# RL6845_IP_SVD register map
Vendor: Realtek
Registers are 32-bit, read-write, reset 0x0 unless marked. A register's access mark holds for its fields unless they carry their own. Offsets are from the block's base; [hi:lo] are bit positions; {n}, {i} and the like mark numbered series.

## PAGE1 (part 2 of 2)
Base 0x40000000
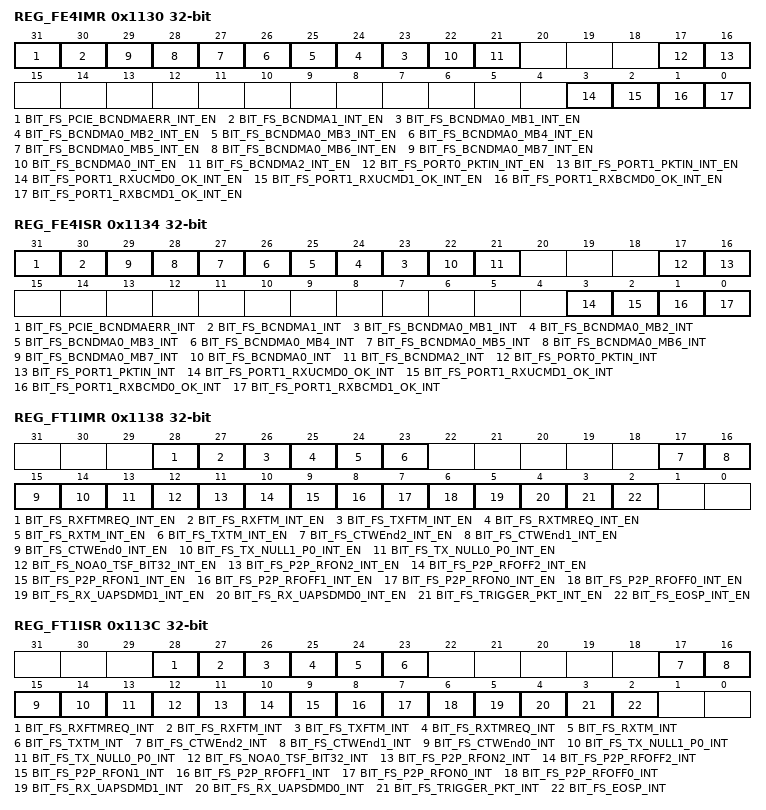
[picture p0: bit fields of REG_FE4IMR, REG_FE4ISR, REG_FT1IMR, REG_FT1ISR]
0x1130 REG_FE4IMR
  [31] BIT_FS_PCIE_BCNDMAERR_INT_EN — PCIE BCN DMA error interrupt
  [30] BIT_FS_BCNDMA1_INT_EN — When BCNDMA interval arrives before TBTT1, this interrupt informs MCU to prepare related beacon tasks.
  [n+22] BIT_FS_BCNDMA0_MB{n}_INT_EN (n=1..7) — When BCNDMA interval arrives before TBTT0_MB{n}, this interrupt informs MCU to prepare related beacon tasks.
  [22] BIT_FS_BCNDMA0_INT_EN — When BCNDMA interval arrives before TBTT0_MB0, this interrupt informs MCU to prepare related beacon tasks.
  [21] BIT_FS_BCNDMA2_INT_EN — When BCNDMA interval arrives before TBTT2, this interrupt informs MCU to prepare related beacon tasks.
  [17] BIT_FS_PORT0_PKTIN_INT_EN — port 0 packet assign to queue interrupt
  [16] BIT_FS_PORT1_PKTIN_INT_EN — port 1 packet assign to queue interrupt
  [3] BIT_FS_PORT1_RXUCMD0_OK_INT_EN — port 1 rx unicast packet with more data = 0 ok interrupt
  [2] BIT_FS_PORT1_RXUCMD1_OK_INT_EN — port 1 rx unicast packet with more data = 1 ok interrupt
  [1] BIT_FS_PORT1_RXBCMD0_OK_INT_EN — port 1 rx broadcast packet with more data = 0 ok interrupt
  [0] BIT_FS_PORT1_RXBCMD1_OK_INT_EN — port 1 rx broadcast packet with more data = 1 ok interrupt
0x1134 REG_FE4ISR ro
  [31] BIT_FS_PCIE_BCNDMAERR_INT — PCIE BCN DMA error interrupt
  [30] BIT_FS_BCNDMA1_INT — When BCNDMA interval arrives before TBTT1, this interrupt informs MCU to prepare related beacon tasks.
  [n+22] BIT_FS_BCNDMA0_MB{n}_INT (n=1..7) — When BCNDMA interval arrives before TBTT0_MB{n}, this interrupt informs MCU to prepare related beacon tasks.
  [22] BIT_FS_BCNDMA0_INT — When BCNDMA interval arrives before TBTT0_MB0, this interrupt informs MCU to prepare related beacon tasks.
  [21] BIT_FS_BCNDMA2_INT — When BCNDMA interval arrives before TBTT2, this interrupt informs MCU to prepare related beacon tasks.
  [17] BIT_FS_PORT0_PKTIN_INT — port 0 packet assign to queue interrupt
  [16] BIT_FS_PORT1_PKTIN_INT — port 1 packet assign to queue interrupt
  [3] BIT_FS_PORT1_RXUCMD0_OK_INT — port 1 rx unicast packet with more data = 0 ok interrupt
  [2] BIT_FS_PORT1_RXUCMD1_OK_INT — port 1 rx unicast packet with more data = 1 ok interrupt
  [1] BIT_FS_PORT1_RXBCMD0_OK_INT — port 1 rx broadcast packet with more data = 0 ok interrupt
  [0] BIT_FS_PORT1_RXBCMD1_OK_INT — port 1 rx broadcast packet with more data = 1 ok interrupt
0x1138 REG_FT1IMR
  [28] BIT_FS_RXFTMREQ_INT_EN — If BIT_RXFTMREQ_INT_EN =1. When HW receive FTMREQ packet, it will generate interrupt to firmware.
  [27] BIT_FS_RXFTM_INT_EN — If BIT_RXFTM_INT_EN =1. When HW receive FTM and transmit ACK frame successfully, the BB generate FTM report. It will generate interrupt to firmware.
  [26] BIT_FS_TXFTM_INT_EN — If BIT_TXFTM_INT_EN =1. When HW transmit FTM and receive ACK frame successfully, the BB generate FTM report. It will generate interrupt to firmware.
  [25] BIT_FS_RXTMREQ_INT_EN — If BIT_RXTMREQ_INT_EN =1. When HW receive TMREQ packet, it will generate interrupt to firmware.
  [24] BIT_FS_RXTM_INT_EN — If BIT_RXTM_INT_EN =1. When HW receive TM and transmit ACK frame successfully. It will generate interrupt to firmware.
  [23] BIT_FS_TXTM_INT_EN — If BIT_TXTM_INT_EN =1. When HW transmit TM and receive ACK frame successfully. It will generate interrupt to firmware.
  [17] BIT_FS_CTWEnd2_INT_EN — CTWindow End NOA2 interrupt.
  [16] BIT_FS_CTWEnd1_INT_EN — CTWindow End NOA1 interrupt.
  [15] BIT_FS_CTWEnd0_INT_EN — CTWindow End NOA0 interrupt.
  [14] BIT_FS_TX_NULL1_P0_INT_EN — TX null 1 packet done interrupt
  [13] BIT_FS_TX_NULL0_P0_INT_EN — TX null 0 packet done interrupt
  [12] BIT_FS_NOA0_TSF_BIT32_INT_EN — NOA unit0 TSFT bit 32 toggle interrupt
  [11] BIT_FS_P2P_RFON2_INT_EN — P2P NoA RF on time indication 2 interrupt
  [10] BIT_FS_P2P_RFOFF2_INT_EN — P2P NoA RF off time indication 2 interrupt
  [9] BIT_FS_P2P_RFON1_INT_EN — P2P NoA RF on time indication 1 interrupt
  [8] BIT_FS_P2P_RFOFF1_INT_EN — P2P NoA RF off time indication 1 interrupt
  [7] BIT_FS_P2P_RFON0_INT_EN — P2P NoA RF on time indication 0 interrupt
  [6] BIT_FS_P2P_RFOFF0_INT_EN — P2P NoA RF off time indication 0 interrupt
  [5] BIT_FS_RX_UAPSDMD1_INT_EN — Setting this bit indicates Rx pkt is matched with one of below: 1.) QoS Unicast data frame with MD=1, UAPSD=0 2.) NonQoS Unicast data frame with MD=1
  [4] BIT_FS_RX_UAPSDMD0_INT_EN — Setting this bit indicates Rx pkt is matched with one of below: 1.) QoS Unicast data frame with MD=0, UAPSD=0 2.) NonQoS Unicast data frame with MD=0
  [3] BIT_FS_TRIGGER_PKT_INT_EN — tx TRIGGER_PKT interrupt
  [2] BIT_FS_EOSP_INT_EN — EOSP_INT interrupt mask
0x113C REG_FT1ISR ro
  [28] BIT_FS_RXFTMREQ_INT — If BIT_RXFTMREQ_INT_EN =1. When HW receive FTMREQ packet, it will generate interrupt to firmware.
  [27] BIT_FS_RXFTM_INT — If BIT_RXFTM_INT_EN =1. When HW receive FTM and transmit ACK frame successfully, the BB generate FTM report. It will generate interrupt to firmware.
  [26] BIT_FS_TXFTM_INT — If BIT_TXFTM_INT_EN =1. When HW transmit FTM and receive ACK frame successfully, the BB generate FTM report. It will generate interrupt to firmware.
  [25] BIT_FS_RXTMREQ_INT — If BIT_RXTMREQ_INT_EN =1. When HW receive TMREQ packet, it will generate interrupt to firmware.
  [24] BIT_FS_RXTM_INT — If BIT_RXTM_INT_EN =1. When HW receive TM and transmit ACK frame successfully. It will generate interrupt to firmware.
  [23] BIT_FS_TXTM_INT — If BIT_TXTM_INT_EN =1. When HW transmit TM and receive ACK frame successfully. It will generate interrupt to firmware.
  [17] BIT_FS_CTWEnd2_INT — CTWindow End NOA2 interrupt.
  [16] BIT_FS_CTWEnd1_INT — CTWindow End NOA1 interrupt.
  [15] BIT_FS_CTWEnd0_INT — CTWindow End NOA0 interrupt.
  [14] BIT_FS_TX_NULL1_P0_INT — TX null 1 packet done interrupt
  [13] BIT_FS_TX_NULL0_P0_INT — TX null 0 packet done interrupt
  [12] BIT_FS_NOA0_TSF_BIT32_INT — NOA unit0 TSFT bit 32 toggle interrupt
  [11] BIT_FS_P2P_RFON2_INT — P2P NoA RF on time indication 2 interrupt
  [10] BIT_FS_P2P_RFOFF2_INT — P2P NoA RF off time indication 2 interrupt
  [9] BIT_FS_P2P_RFON1_INT — P2P NoA RF on time indication 1 interrupt
  [8] BIT_FS_P2P_RFOFF1_INT — P2P NoA RF off time indication 1 interrupt
  [7] BIT_FS_P2P_RFON0_INT — P2P NoA RF on time indication 0 interrupt
  [6] BIT_FS_P2P_RFOFF0_INT — P2P NoA RF off time indication 0 interrupt
  [5] BIT_FS_RX_UAPSDMD1_INT — Setting this bit indicates Rx pkt is matched with one of below: 1.) QoS Unicast data frame with MD=1, UAPSD=0 2.) NonQoS Unicast data frame with MD=1
  [4] BIT_FS_RX_UAPSDMD0_INT — Setting this bit indicates Rx pkt is matched with one of below: 1.) QoS Unicast data frame with MD=0, UAPSD=0 2.) NonQoS Unicast data frame with MD=0
  [3] BIT_FS_TRIGGER_PKT_INT — tx TRIGGER_PKT interrupt
  [2] BIT_FS_EOSP_INT — EOSP_INT interrupt mask
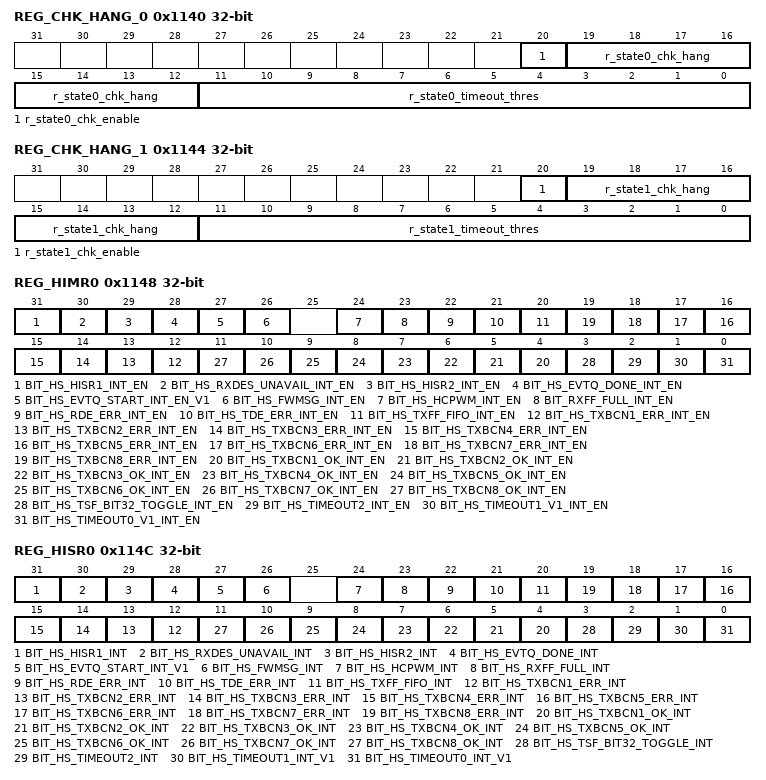
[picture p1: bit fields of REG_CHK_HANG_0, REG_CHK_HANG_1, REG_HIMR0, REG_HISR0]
0x1140 REG_CHK_HANG_0
  [20] r_state0_chk_enable — function enable of check hang of state_0
  [19:12] r_state0_chk_hang — when r_state0_chk_enable is set, if state_0 is the value is equal to r_state0_chk_hang, starts state0_timeout_timer
  [11:0] r_state0_timeout_thres — timeout threshold of state0_timeout_timer, unit:us
0x1144 REG_CHK_HANG_1
  [20] r_state1_chk_enable — function enable of check hang of state_1
  [19:12] r_state1_chk_hang — when r_state1_chk_enable is set, if state_1 is the value is equal to r_state1_chk_hang, starts state1_timeout_timer
  [11:0] r_state1_timeout_thres — timeout threshold of state0_timeout_timer, unit:us
0x1148 REG_HIMR0
  [31] BIT_HS_HISR1_INT_EN — HISR1 Indicator (HIISR1 andHIMR1 are true, this bit is set to 1)
  [30] BIT_HS_RXDES_UNAVAIL_INT_EN — Rx Descriptor Unavailable
  [29] BIT_HS_HISR2_INT_EN — HISR2 Indicator (HIISR2 andHIMR2 are true, this bit is set to 1)
  [28] BIT_HS_EVTQ_DONE_INT_EN — event queue done interrupt for NAN
  [27] BIT_HS_EVTQ_START_INT_EN_V1 — event queue start interrupt for NAN
  [26] BIT_HS_FWMSG_INT_EN — FW message interrupt,CPU to Host Command INT Status, Write 1 clear
  [24] BIT_HS_HCPWM_INT_EN — CPWM interrupt,CPU power Mode exchange INT Status, Write 1 clear
  [23] BIT_RXFF_FULL_INT_EN — Rxpktbuffer full interrupt
  [22] BIT_HS_RDE_ERR_INT_EN — Rxdma error interrupt
  [21] BIT_HS_TDE_ERR_INT_EN — Txdma error interrupt
  [20] BIT_HS_TXFF_FIFO_INT_EN — txpktbuffer full interrupt
  [n+11] BIT_HS_TXBCN{n}_ERR_INT_EN (n=1..8) — port0 BSSID{n-1} TX beacon error interrupt
  [n+3] BIT_HS_TXBCN{n}_OK_INT_EN (n=1..8) — port0 BSSID{n-1} TX beacon ok interrupt
  [3] BIT_HS_TSF_BIT32_TOGGLE_INT_EN — TSF Timer BIT32 toggle indication interrupt
  [2] BIT_HS_TIMEOUT2_INT_EN — tsf Timer2 interrupt
  [1] BIT_HS_TIMEOUT1_V1_INT_EN — tsf Timer1 interrupt
  [0] BIT_HS_TIMEOUT0_V1_INT_EN — tsf Timer0 interrupt
0x114C REG_HISR0 ro
  [31] BIT_HS_HISR1_INT — HISR1 Indicator (HIISR1 andHIMR1 are true, this bit is set to 1)
  [30] BIT_HS_RXDES_UNAVAIL_INT — Rx Descriptor Unavailable
  [29] BIT_HS_HISR2_INT — HISR2 Indicator (HIISR2 andHIMR2 are true, this bit is set to 1)
  [28] BIT_HS_EVTQ_DONE_INT — event queue done interrupt for NAN
  [27] BIT_HS_EVTQ_START_INT_V1 — event queue start interrupt for NAN
  [26] BIT_HS_FWMSG_INT — FW message interrupt,CPU to Host Command INT Status, Write 1 clear
  [24] BIT_HS_HCPWM_INT — CPWM interrupt,CPU power Mode exchange INT Status, Write 1 clear
  [23] BIT_HS_RXFF_FULL_INT — Rxpktbuffer full interrupt
  [22] BIT_HS_RDE_ERR_INT — Rxdma error interrupt
  [21] BIT_HS_TDE_ERR_INT — Txdma error interrupt
  [20] BIT_HS_TXFF_FIFO_INT — txpktbuffer full interrupt
  [n+11] BIT_HS_TXBCN{n}_ERR_INT (n=1..8) — port0 BSSID{n-1} TX beacon error interrupt
  [n+3] BIT_HS_TXBCN{n}_OK_INT (n=1..8) — port0 BSSID{n-1} TX beacon ok interrupt
  [3] BIT_HS_TSF_BIT32_TOGGLE_INT — TSF Timer BIT32 toggle indication interrupt
  [2] BIT_HS_TIMEOUT2_INT — tsf Timer2 interrupt
  [1] BIT_HS_TIMEOUT1_INT_V1 — tsf Timer1 interrupt
  [0] BIT_HS_TIMEOUT0_INT_V1 — tsf Timer0 interrupt
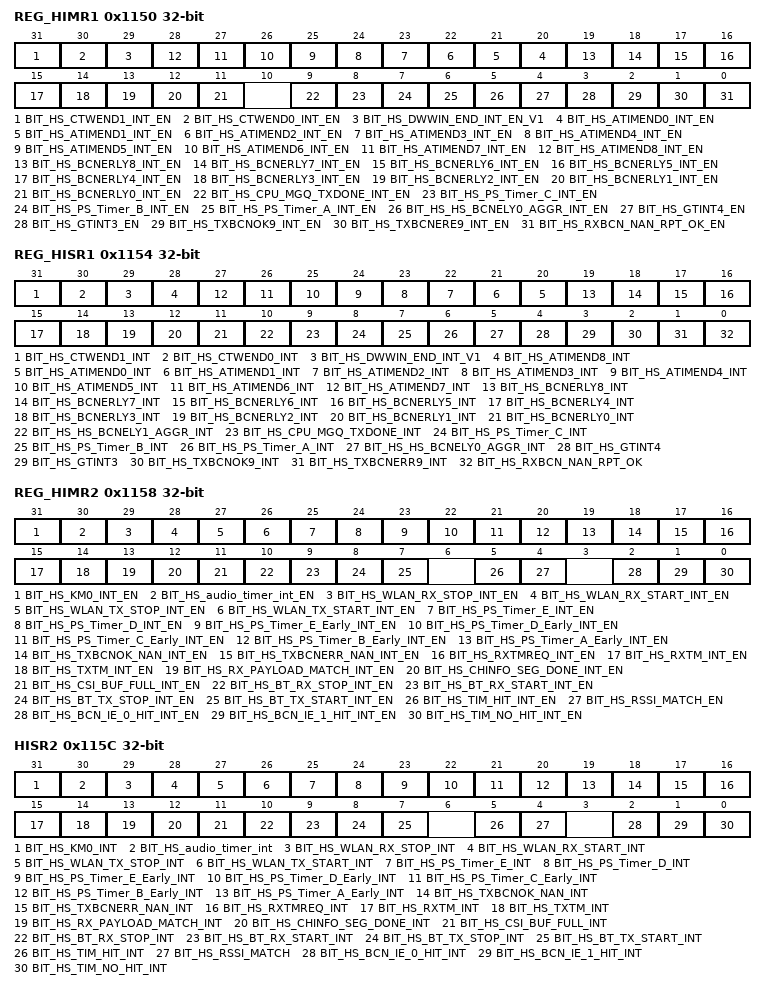
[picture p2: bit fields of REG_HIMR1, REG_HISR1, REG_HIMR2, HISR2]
0x1150 REG_HIMR1
  [31] BIT_HS_CTWEND1_INT_EN — Client1 traffic window end interrupt for P2P
  [30] BIT_HS_CTWEND0_INT_EN — Client0 traffic window end interrupt for P2P
  [29] BIT_HS_DWWIN_END_INT_EN_V1 — discovery window end interrupt for NAN
  [n+20] BIT_HS_ATIMEND{n}_INT_EN (n=0..8) — port0 BSSID{n} atimend interrupt
  [19] BIT_HS_BCNERLY8_INT_EN — port1 beacon early interrupt
  [18] BIT_HS_BCNERLY7_INT_EN — port0 BSSID7 beacon early interrupt , only valid under MBSSID mode
  [17] BIT_HS_BCNERLY6_INT_EN — port0 BSSID6 beacon early interrupt , only valid under MBSSID mode
  [16] BIT_HS_BCNERLY5_INT_EN — port0 BSSID5 beacon early interrupt , only valid under MBSSID mode
  [15] BIT_HS_BCNERLY4_INT_EN — port0 BSSID4 beacon early interrupt, only valid under MBSSID mode
  [14] BIT_HS_BCNERLY3_INT_EN — port0 BSSID3 beacon early interrupt , only valid under MBSSID mode
  [13] BIT_HS_BCNERLY2_INT_EN — port0 BSSID2 beacon early interrupt, only valid under MBSSID mode
  [12] BIT_HS_BCNERLY1_INT_EN — port0 BSSID1 beacon early interrupt , only valid under MBSSID mode
  [11] BIT_HS_BCNERLY0_INT_EN — This interrupt is issued at the time set by DRVERLYINT register before TBTT time for port 0 root bssid
  [9] BIT_HS_CPU_MGQ_TXDONE_INT_EN — CPU_MQG_TXDONE ineterrupt source when HW TX CPUMGQ packet success, it issue interrupt to host
  [8] BIT_HS_PS_Timer_C_INT_EN — PS_Timer_C interrupt source When the lower 4 bytes of TSF(that select by reg 0x1510[18:16]) matches the content of this register, the PS_Timer_C_INT interrupt is issued
  [7] BIT_HS_PS_Timer_B_INT_EN — PS_Timer_B interrupt source When the lower 4 bytes of TSF(that select by reg 0x1510[10:8]) matches the content of this register, the PS_Timer_B_INT interrupt is issued
  [6] BIT_HS_PS_Timer_A_INT_EN — PS_Timer_A interrupt source When the lower 4 bytes of TSF(that select by reg 0x1510[2:0]) matches the content of this register, the PS_Timer_A_INT interrupt is issued
  [5] BIT_HS_HS_BCNELY0_AGGR_INT_EN — port 0 Beacon early aggregation interrupt
  [4] BIT_HS_GTINT4_EN — When GTIMER4 expires, this bit is set to 1
  [3] BIT_HS_GTINT3_EN — When GTIMER3 expires, this bit is set to 1
  [2] BIT_HS_TXBCNOK9_INT_EN — PORT1 TX beacon OK interrupt
  [1] BIT_HS_TXBCNERE9_INT_EN — PORT1 TX beacon Error interrupt
  [0] BIT_HS_RXBCN_NAN_RPT_OK_EN — port2 rxbcn rpt and write to txrptbuf ok
0x1154 REG_HISR1 ro
  [31] BIT_HS_CTWEND1_INT — Client1 traffic window end interrupt for P2P
  [30] BIT_HS_CTWEND0_INT — Client0 traffic window end interrupt for P2P
  [29] BIT_HS_DWWIN_END_INT_V1 — discovery window end interrupt for NAN
  [28] BIT_HS_ATIMEND8_INT — port1 atimend interrupt
  [n+20] BIT_HS_ATIMEND{n}_INT (n=0..7) — port0 BSSID{n} atimend interrupt
  [19] BIT_HS_BCNERLY8_INT — port1 beacon early interrupt
  [18] BIT_HS_BCNERLY7_INT — port0 BSSID7 beacon early interrupt , only valid under MBSSID mode
  [17] BIT_HS_BCNERLY6_INT — port0 BSSID6 beacon early interrupt , only valid under MBSSID mode
  [16] BIT_HS_BCNERLY5_INT — port0 BSSID5 beacon early interrupt , only valid under MBSSID mode
  [15] BIT_HS_BCNERLY4_INT — port0 BSSID4 beacon early interrupt, only valid under MBSSID mode
  [14] BIT_HS_BCNERLY3_INT — port0 BSSID3 beacon early interrupt , only valid under MBSSID mode
  [13] BIT_HS_BCNERLY2_INT — port0 BSSID2 beacon early interrupt, only valid under MBSSID mode
  [12] BIT_HS_BCNERLY1_INT — port0 BSSID1 beacon early interrupt , only valid under MBSSID mode
  [11] BIT_HS_BCNERLY0_INT — This interrupt is issued at the time set by DRVERLYINT register before TBTT time for port 0 root bssid
  [10] BIT_HS_HS_BCNELY1_AGGR_INT — port 1 Beacon early aggregation interrupt
  [9] BIT_HS_CPU_MGQ_TXDONE_INT — CPU_MQG_TXDONE ineterrupt source when HW TX CPUMGQ packet success, it issue interrupt to host
  [8] BIT_HS_PS_Timer_C_INT — PS_Timer_C interrupt source When the lower 4 bytes of TSF(that select by reg 0x1510[18:16]) matches the content of this register, the PS_Timer_C_INT interrupt is issued
  [7] BIT_HS_PS_Timer_B_INT — PS_Timer_B interrupt source When the lower 4 bytes of TSF(that select by reg 0x1510[10:8]) matches the content of this register, the PS_Timer_B_INT interrupt is issued
  [6] BIT_HS_PS_Timer_A_INT — PS_Timer_A interrupt source When the lower 4 bytes of TSF(that select by reg 0x1510[2:0]) matches the content of this register, the PS_Timer_A_INT interrupt is issued
  [5] BIT_HS_HS_BCNELY0_AGGR_INT — port 0 Beacon early aggregation interrupt
  [4] BIT_HS_GTINT4 — When GTIMER4 expires, this bit is set to 1
  [3] BIT_HS_GTINT3 — When GTIMER3 expires, this bit is set to 1
  [2] BIT_HS_TXBCNOK9_INT — PORT1 TX beacon OK interrupt
  [1] BIT_HS_TXBCNERR9_INT — PORT1 TX beacon Error interrupt
  [0] BIT_HS_RXBCN_NAN_RPT_OK — port2 rxbcn rpt and write to txrptbuf ok
0x1158 REG_HIMR2
  [31] BIT_HS_KM0_INT_EN — The gathering of interrupts of KM0
  [30] BIT_HS_audio_timer_int_EN — if the counter of rxbcn(P0 rx mode) or TBTT(P1/P0 tx mode) reached the threshold, generate an interrupt to notify the Driver
  [29] BIT_HS_WLAN_RX_STOP_INT_EN — From wmac. BIT_WLAN_RX_START=(pre_wl_cca==1)&&(cur_wl_cca==0)
  [28] BIT_HS_WLAN_RX_START_INT_EN — From wmac. BIT_WLAN_RX_START=(pre_wl_cca==0)&&(cur_wl_cca==1) Zigbee
  [27] BIT_HS_WLAN_TX_STOP_INT_EN — From wmac. BIT_WLAN_TX_START=(pre_wl_mactxen==1)&&(cur_wl_mactxen=0)
  [26] BIT_HS_WLAN_TX_START_INT_EN — From wmac. BIT_WLAN_TX_START=(pre_wl_mactxen==0)&&(cur_wl_mactxen=1) Zigbee
  [25] BIT_HS_PS_Timer_E_INT_EN — PS_Timer_E interrupt When the TSF(that select by reg 0x1520[13:12]) matches the content of this register, the PS_Timer_E_INT interrupt is issued
  [24] BIT_HS_PS_Timer_D_INT_EN — PS_Timer_D interrupt When the lower 4 bytes of TSF(that select by reg 0x1520[17:16]) matches the content of this register, the PS_Timer_D_INT interrupt is issued
  [23] BIT_HS_PS_Timer_E_Early_INT_EN — This interrupt is issued at the time set by PS_Timer_E_Early register before PS_Timer_E time.
  [22] BIT_HS_PS_Timer_D_Early_INT_EN — This interrupt is issued at the time set by PS_Timer_D_Early register before PS_Timer_D time.
  [21] BIT_HS_PS_Timer_C_Early_INT_EN — This interrupt is issued at the time set by PS_Timer_C_Early register before PS_Timer_C time.
  [20] BIT_HS_PS_Timer_B_Early_INT_EN — This interrupt is issued at the time set by PS_Timer_B_Early register before PS_Timer_B time.
  [19] BIT_HS_PS_Timer_A_Early_INT_EN — This interrupt is issued at the time set by PS_Timer_A_Early register before PS_Timer_A time.
  [18] BIT_HS_TXBCNOK_NAN_INT_EN — PORT2 TX beacon OK interrupt
  [17] BIT_HS_TXBCNERR_NAN_INT_EN — PORT2 TX beacon Error interrupt
  [16] BIT_HS_RXTMREQ_INT_EN — If BIT_RXTMREQ_INT_EN =1. When HW receive TMREQ packet, it will generate interrupt to firmware.
  [15] BIT_HS_RXTM_INT_EN — If BIT_RXTM_INT_EN =1. When HW receive TM and transmit ACK frame successfully. It will generate interrupt to firmware.
  [14] BIT_HS_TXTM_INT_EN — If BIT_TXTM_INT_EN =1. When HW transmit TM and receive ACK frame successfully. It will generate interrupt to firmware.
  [13] BIT_HS_RX_PAYLOAD_MATCH_INT_EN — indicate rx payload content match
  [12] BIT_HS_CHINFO_SEG_DONE_INT_EN — indicate one channel info segment is received ok
  [11] BIT_HS_CSI_BUF_FULL_INT_EN — indicate channel info rxcsibuffer is full
  [10] BIT_HS_BT_RX_STOP_INT_EN — From PTA. BIT_BT_TX_START=(pre_gnt_bt_rx==1) &&(cur_gnt_bt_rx==0)
  [9] BIT_HS_BT_RX_START_INT_EN — From PTA. BIT_BT_TX_START=(pre_gnt_bt_rx==0) &&(cur_gnt_bt_rx==1)
  [8] BIT_HS_BT_TX_STOP_INT_EN — From PTA. BIT_BT_TX_START=(pre_gnt_bt_tx==1) &&(cur_gnt_bt_tx==0)
  [7] BIT_HS_BT_TX_START_INT_EN — From PTA. BIT_BT_TX_START=(pre_gnt_bt_tx==0) &&(cur_gnt_bt_tx==1)
  [5] BIT_HS_TIM_HIT_INT_EN — when my aid or aid is 0 (0x16DC[8]) or my bssid is in tim element,generate this interrupt
  [4] BIT_HS_RSSI_MATCH_EN — Interrupt to inform km0 received RSSI is in supposed range
  [2] BIT_HS_BCN_IE_0_HIT_INT_EN — rx bcn with ie0 hit
  [1] BIT_HS_BCN_IE_1_HIT_INT_EN — rx bcn with ie1 hit
  [0] BIT_HS_TIM_NO_HIT_INT_EN — when no my aid or aid is 0(0x16DC[8]) or my bssid is not in tim element(0x16DB[31]),generate this interrupt
0x115C HISR2 ro
  [31] BIT_HS_KM0_INT — The gathering of interrupts of KM0
  [30] BIT_HS_audio_timer_int — if the counter of rxbcn(P0 rx mode) or TBTT(P1/P0 tx mode) reached the threshold, generate an interrupt to notify the Driver
  [29] BIT_HS_WLAN_RX_STOP_INT — From wmac. BIT_WLAN_RX_START=(pre_wl_cca==1)&&(cur_wl_cca==0)
  [28] BIT_HS_WLAN_RX_START_INT — From wmac. BIT_WLAN_RX_START=(pre_wl_cca==0)&&(cur_wl_cca==1) Zigbee 收到该中断后,可以选择是否要中断当前封包TX or RX
  [27] BIT_HS_WLAN_TX_STOP_INT — From wmac. BIT_WLAN_TX_START=(pre_wl_mactxen==1)&&(cur_wl_mactxen=0)
  [26] BIT_HS_WLAN_TX_START_INT — From wmac. BIT_WLAN_TX_START=(pre_wl_mactxen==0)&&(cur_wl_mactxen=1) Zigbee 收到该中断后,可以选择是否要中断当前封包TX or RX
  [25] BIT_HS_PS_Timer_E_INT — PS_Timer_E interrupt When the TSF(that select by reg 0x1520[13:12]) matches the content of this register, the PS_Timer_E_INT interrupt is issued
  [24] BIT_HS_PS_Timer_D_INT — PS_Timer_D interrupt When the lower 4 bytes of TSF(that select by reg 0x1520[17:16]) matches the content of this register, the PS_Timer_D_INT interrupt is issued
  [23] BIT_HS_PS_Timer_E_Early_INT — This interrupt is issued at the time set by PS_Timer_E_Early register before PS_Timer_E time.
  [22] BIT_HS_PS_Timer_D_Early_INT — This interrupt is issued at the time set by PS_Timer_D_Early register before PS_Timer_D time.
  [21] BIT_HS_PS_Timer_C_Early_INT — This interrupt is issued at the time set by PS_Timer_C_Early register before PS_Timer_C time.
  [20] BIT_HS_PS_Timer_B_Early_INT — This interrupt is issued at the time set by PS_Timer_B_Early register before PS_Timer_B time.
  [19] BIT_HS_PS_Timer_A_Early_INT — This interrupt is issued at the time set by PS_Timer_A_Early register before PS_Timer_A time.
  [18] BIT_HS_TXBCNOK_NAN_INT — PORT2 TX beacon OK interrupt
  [17] BIT_HS_TXBCNERR_NAN_INT — PORT2 TX beacon Error interrupt
  [16] BIT_HS_RXTMREQ_INT — If BIT_RXTMREQ_INT_EN =1. When HW receive TMREQ packet, it will generate interrupt to firmware.
  [15] BIT_HS_RXTM_INT — If BIT_RXTM_INT_EN =1. When HW receive TM and transmit ACK frame successfully. It will generate interrupt to firmware.
  [14] BIT_HS_TXTM_INT — If BIT_TXTM_INT_EN =1. When HW transmit TM and receive ACK frame successfully. It will generate interrupt to firmware.
  [13] BIT_HS_RX_PAYLOAD_MATCH_INT — indicate rx payload content match
  [12] BIT_HS_CHINFO_SEG_DONE_INT — indicate one channel info segment is received ok
  [11] BIT_HS_CSI_BUF_FULL_INT — indicate channel info rxcsibuffer is full
  [10] BIT_HS_BT_RX_STOP_INT — From PTA. BIT_BT_TX_START=(pre_gnt_bt_rx==1) &&(cur_gnt_bt_rx==0)
  [9] BIT_HS_BT_RX_START_INT — From PTA. BIT_BT_TX_START=(pre_gnt_bt_rx==0) &&(cur_gnt_bt_rx==1)
  [8] BIT_HS_BT_TX_STOP_INT — From PTA. BIT_BT_TX_START=(pre_gnt_bt_tx==1) &&(cur_gnt_bt_tx==0)
  [7] BIT_HS_BT_TX_START_INT — From PTA. BIT_BT_TX_START=(pre_gnt_bt_tx==0) &&(cur_gnt_bt_tx==1)
  [5] BIT_HS_TIM_HIT_INT — when my aid or aid is 0 (0x16DC[8]) or my bssid is in tim element,generate this interrupt
  [4] BIT_HS_RSSI_MATCH — Interrupt to inform km0 received RSSI is in supposed range
  [2] BIT_HS_BCN_IE_0_HIT_INT — rx bcn with ie0 hit
  [1] BIT_HS_BCN_IE_1_HIT_INT — rx bcn with ie1 hit
  [0] BIT_HS_TIM_NO_HIT_INT — when no my aid or aid is 0(0x16DC[8]) or my bssid is not in tim element(0x16DB[31]),generate this interrupt
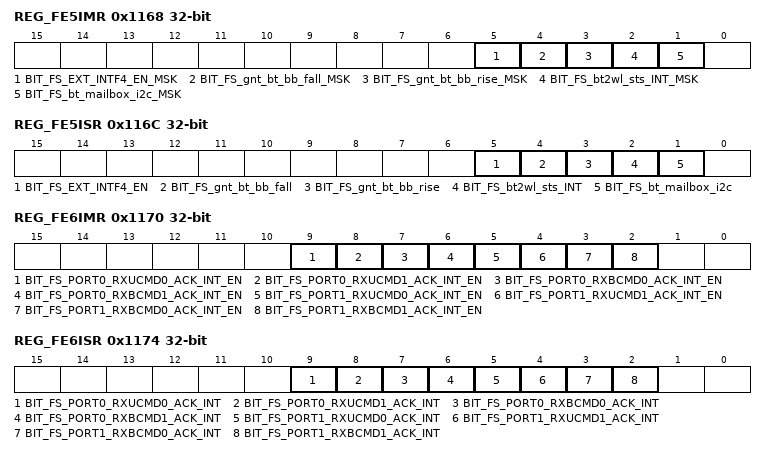
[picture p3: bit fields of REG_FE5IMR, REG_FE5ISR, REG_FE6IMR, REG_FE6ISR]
0x1168 REG_FE5IMR
  [5] BIT_FS_EXT_INTF4_EN_MSK — ext bt mailbox int,mailbox_outempty_int| mailbox_in_rdy_int
  [4] BIT_FS_gnt_bt_bb_fall_MSK — ext Mailbox INT from btcoex
  [3] BIT_FS_gnt_bt_bb_rise_MSK — ext Mailbox INT from btcoex
  [2] BIT_FS_bt2wl_sts_INT_MSK — ext scoreboard INT from BT
  [1] BIT_FS_bt_mailbox_i2c_MSK — Mailbox INT from I2C
0x116C REG_FE5ISR ro
  [5] BIT_FS_EXT_INTF4_EN — ext bt mailbox int,mailbox_outempty_int| mailbox_in_rdy_int
  [4] BIT_FS_gnt_bt_bb_fall — ext Mailbox INT from btcoex
  [3] BIT_FS_gnt_bt_bb_rise — ext Mailbox INT from btcoex
  [2] BIT_FS_bt2wl_sts_INT — ext scoreboard INT from BT
  [1] BIT_FS_bt_mailbox_i2c — Mailbox INT from I2C
0x1170 REG_FE6IMR access per field
  [9] BIT_FS_PORT0_RXUCMD0_ACK_INT_EN rw — port 0 rx unicast ACK/BA/MBA with more data = 0 ok interrupt
  [8] BIT_FS_PORT0_RXUCMD1_ACK_INT_EN rw — port 0 rx unicast ACK/BA/MBA with more data = 1 ok interrupt
  [7] BIT_FS_PORT0_RXBCMD0_ACK_INT_EN rw — port 0 rx broadcast ACK/BA/MBA with more data = 0 ok interrupt
  [6] BIT_FS_PORT0_RXBCMD1_ACK_INT_EN rw — port 0 rx broadcast ACK/BA/MBA with more data = 1 ok interrupt
  [5] BIT_FS_PORT1_RXUCMD0_ACK_INT_EN rw — port 1 rx unicast ACK/BA/MBA with more data = 0 ok interrupt
  [4] BIT_FS_PORT1_RXUCMD1_ACK_INT_EN rw — port 1 rx unicast ACK/BA/MBA with more data = 1 ok interrupt
  [3] BIT_FS_PORT1_RXBCMD0_ACK_INT_EN rw — port 1 rx broadcast ACK/BA/MBA with more data = 0 ok interrupt
  [2] BIT_FS_PORT1_RXBCMD1_ACK_INT_EN rw — port 1 rx broadcast ACK/BA/MBA with more data = 1 ok interrupt
0x1174 REG_FE6ISR access per field
  [9] BIT_FS_PORT0_RXUCMD0_ACK_INT ro — port 0 rx unicast ACK/BA/MBA with more data = 0 ok interrupt
  [8] BIT_FS_PORT0_RXUCMD1_ACK_INT ro — port 0 rx unicast ACK/BA/MBA with more data = 1 ok interrupt
  [7] BIT_FS_PORT0_RXBCMD0_ACK_INT ro — port 0 rx broadcast ACK/BA/MBA with more data = 0 ok interrupt
  [6] BIT_FS_PORT0_RXBCMD1_ACK_INT ro — port 0 rx broadcast ACK/BA/MBA with more data = 1 ok interrupt
  [5] BIT_FS_PORT1_RXUCMD0_ACK_INT ro — port 1 rx unicast ACK/BA/MBA with more data = 0 ok interrupt
  [4] BIT_FS_PORT1_RXUCMD1_ACK_INT ro — port 1 rx unicast ACK/BA/MBA with more data = 1 ok interrupt
  [3] BIT_FS_PORT1_RXBCMD0_ACK_INT ro — port 1 rx broadcast ACK/BA/MBA with more data = 0 ok interrupt
  [2] BIT_FS_PORT1_RXBCMD1_ACK_INT ro — port 1 rx broadcast ACK/BA/MBA with more data = 1 ok interrupt
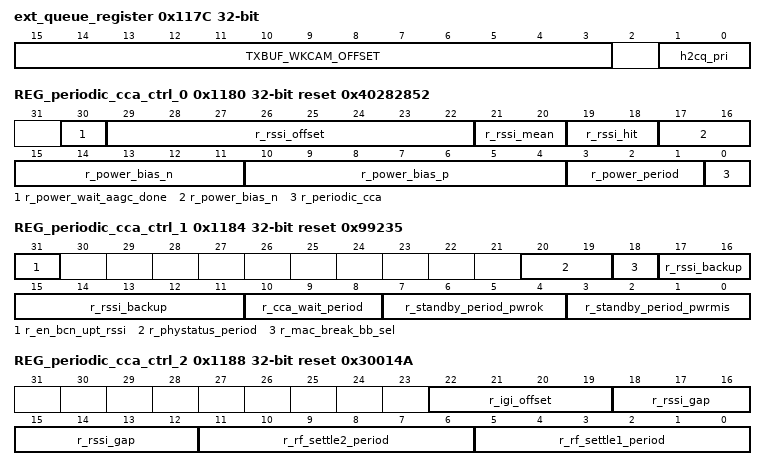
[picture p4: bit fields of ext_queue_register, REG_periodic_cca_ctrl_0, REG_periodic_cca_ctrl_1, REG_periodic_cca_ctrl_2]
0x117C ext_queue_register
  [15:3] TXBUF_WKCAM_OFFSET — the offset of WOL pattern stored in txpktbuffer, unit is 8byte
  [1:0] h2cq_pri
0x1180 REG_periodic_cca_ctrl_0 reset 0x40282852
  [30] r_power_wait_aagc_done — set1:when cca rsie up before power detect done,wait aagc_done to reenter power detect
  [29:22] r_rssi_offset — S(8,0), offset for beacon rssi(signed)
  [21:20] r_rssi_mean — RSSI LATCH mean by 1cycle/2cycle/4 cycle/8cycle
  [19:18] r_rssi_hit — RSSI hit with 1cycle/2cycle/4cycle/8cylce
  [17:11] r_power_bias_n — Power calculated by aagc model compared with r_rssi_backup minus r_power_bias_n(unsigned)
  [10:4] r_power_bias_p — Power calculated by aagc model compared with r_rssi_backup plus r_power_bias_p(unsigned)
  [3:1] r_power_period — Period time for calculate power 0:0.8us /1:1.6us /2:2.4us 3:3.2us /4:4.0us /5:4.8us 6:5.6us /7:6.4us
  [0] r_periodic_cca — Enable or disable periodic cca function when rxbcn
0x1184 REG_periodic_cca_ctrl_1 reset 0x99235
  [31] r_en_bcn_upt_rssi — 1: enable HW update RSSI_BACKUP to 0x1184[17:11] when rx_my_bcn_rdy valid
  [20:19] r_phystatus_period — Period time for cca end to data on end and phystatus upload and RF settling 0:1us /1:2us /2:3us/ 3:4us
  [18] r_mac_break_bb_sel — 0: use BBRST=0 (function disable) to break bb 1:use CCKRST(disable CCK function) to break bb
  [17:11] r_rssi_backup — Backup rssi (unsigned)
  [10:8] r_cca_wait_period — Wait time for CCK CCA 0:5us /1:10us /2:15us 3:20us /4:25us /5:30us 6:35us /7:40us
  [7:4] r_standby_period_pwrok — Period time for RF standby if power is match 0:30us/1:35us /1:40us/ 2:45us/ 3:50us 4:55us /5:60us.. 14:105us/ 15:110us
  [3:0] r_standby_period_pwrmis — Period time for RF standby if power is mismatch 0:30us/1:35us /1:40us/ 2:45us/ 3:50us 4:55us /5:60us.. 14:105us/ 15:110us
0x1188 REG_periodic_cca_ctrl_2 reset 0x30014A
  [22:19] r_igi_offset — S(4,0), offset for beacon rssi(unsigned)
  [18:12] r_rssi_gap — if the difference of average rssi between state of power monitor and state of wait cca is too large(>=r_rssi_gap),the cca will be thought as false alarm
  [11:6] r_rf_settle2_period — settling time for RF if BB & RF is already enabled, 0:0us, 1:0.2us, 2:0.4us...
  [5:0] r_rf_settle1_period — settling time for RF if BB & RF is enabled form standby mode, 0:0us, 1:0.2us, 2:0.4us...
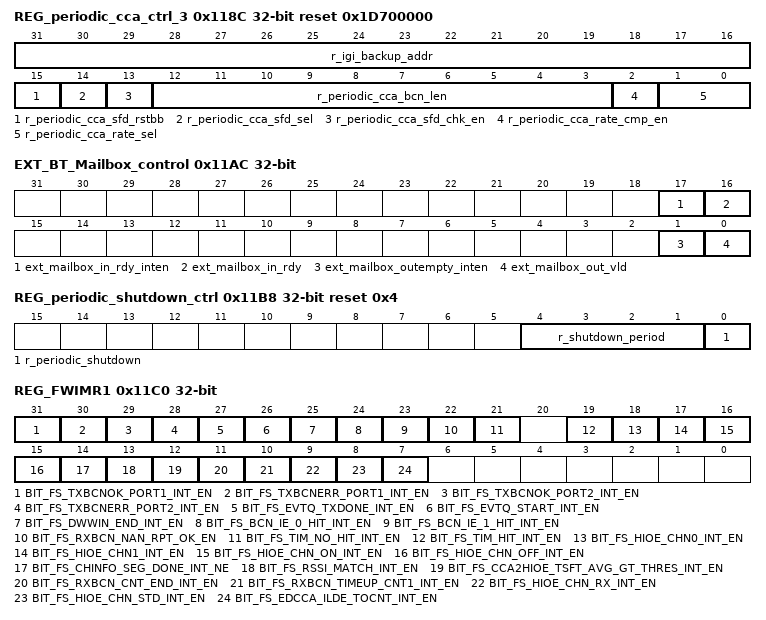
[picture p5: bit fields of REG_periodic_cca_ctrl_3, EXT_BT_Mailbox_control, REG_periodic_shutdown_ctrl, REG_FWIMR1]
0x118C REG_periodic_cca_ctrl_3 reset 0x1D700000
  [31:16] r_igi_backup_addr — Reg address for igi information (for amebad,igi reg is set in BB reg 0x1d70)
  [15] r_periodic_cca_sfd_rstbb — 1:mac check sfd fail will rstbb 0:mac check sfd fail will not rstbb
  [14] r_periodic_cca_sfd_sel — 0:check sfd of long plcp of received beacon 1:check sfd of short plcp of received beacon
  [13] r_periodic_cca_sfd_chk_en — Enable check long plcp preamble or short preamble
  [12:3] r_periodic_cca_bcn_len — Supposed Length of beacon, unit:byte If set to 0, not check length of beacon
  [2] r_periodic_cca_rate_cmp_en — 1:enable rate compare when periodic cca 0:disable rate compare when periodic cca
  [1:0] r_periodic_cca_rate_sel — If rate mismatch, break bb 0:CCK 1M; 1:CCK 2M; 2:CCK 5.5M; 3:CCK11M
0x11A4 EXT_BT_MAILBOX_OUT_LOW
  [31:0] ext_mailbox_data_51to81_l
0x11A8 EXT_BT_MAILBOX_OUT_HIGH
  [31:0] ext_mailbox_data_51to81_h
0x11AC EXT_BT_Mailbox_control access per field
  [17] ext_mailbox_in_rdy_inten rw — Mailbox IN ready interrupt enable
  [16] ext_mailbox_in_rdy ro — Mailbox ready BT2Wifi
  [1] ext_mailbox_outempty_inten rw — Mailbox OUT empty interrupt enable
  [0] ext_mailbox_out_vld ro — Mailbox ACK Wifi2BT
0x11B0 EXT_BT_MAILBOX_IN_LOW ro
  [31:0] ext_mailbox_data_81to51_l
0x11B4 EXT_BT_MAILBOX_IN_HIGH ro
  [31:0] ext_mailbox_data_81_to51_h
0x11B8 REG_periodic_shutdown_ctrl reset 0x4
  [4:1] r_shutdown_period — Period time for RF shutdown if power is match 0:60us /1:80us/ 2:100us/ 3:120us 4:140us /5:160us.. 14:340us/ 15:360us
  [0] r_periodic_shutdown — Enable or disable periodic shutdown BB&RF
0x11C0 REG_FWIMR1
  [31] BIT_FS_TXBCNOK_PORT1_INT_EN — ENABLE PORT1 TX beacon OK interrupt
  [30] BIT_FS_TXBCNERR_PORT1_INT_EN — ENABLE PORT0 TX beacon Error interrupt
  [29] BIT_FS_TXBCNOK_PORT2_INT_EN — PORT2 TX beacon OK interrupt
  [28] BIT_FS_TXBCNERR_PORT2_INT_EN — PORT2 TX beacon Error interrupt
  [27] BIT_FS_EVTQ_TXDONE_INT_EN
  [26] BIT_FS_EVTQ_START_INT_EN
  [25] BIT_FS_DWWIN_END_INT_EN
  [24] BIT_FS_BCN_IE_0_HIT_INT_EN — rx bcn with ie0 hit
  [23] BIT_FS_BCN_IE_1_HIT_INT_EN — rx bcn with ie1 hit
  [22] BIT_FS_RXBCN_NAN_RPT_OK_EN — port2 rxbcn rpt and write to txrptbuf ok
  [21] BIT_FS_TIM_NO_HIT_INT_EN — when no my aid or aid is 0(0x16DC[8]) or my bssid is not in tim element(0x16DB[31]),generate this interrupt
  [19] BIT_FS_TIM_HIT_INT_EN — when my aid or aid is 0 (0x16DC[8]=0) or my bssid is in tim element(0x16D8[31]=0),generate this interrupt
  [18] BIT_FS_HIOE_CHN0_INT_EN — hioe_chn0 done interrupt
  [17] BIT_FS_HIOE_CHN1_INT_EN — hioe_chn1 done interrupt
  [16] BIT_FS_HIOE_CHN_ON_INT_EN — hioe_chn_on done interrupt
  [15] BIT_FS_HIOE_CHN_OFF_INT_EN — hioe_chn_off done interrupt
  [14] BIT_FS_CHINFO_SEG_DONE_INT_NE — indicate one channel info segment is received ok
  [13] BIT_FS_RSSI_MATCH_INT_EN — Interrupt to inform km0 received RSSI is in supposed range
  [12] BIT_FS_CCA2HIOE_TSFT_AVG_GT_THRES_INT_EN — If the BIT_TSFT_AVG_VALUE exceeds the BIT_TSFT_AVG_THRES several times in a row, and the number exceeds the BIT_TSFT_AVG_GT_THRES_CNT_MAX, generate an interrupt.
  [11] BIT_FS_RXBCN_CNT_END_INT_EN — Generate the interrupt when RXBCN period cnt == 2^ BIT_RXBCN_CNT_PRD
  [10] BIT_FS_RXBCN_TIMEUP_CNT1_INT_EN — the interrupt is issued when RX beacon frame timeout occurs specified times in port0.specified by 0x10A[22:16](only enabled when 0x17C[26]=1)
  [9] BIT_FS_HIOE_CHN_RX_INT_EN — hioe_chn_radio_rx done interrupt
  [8] BIT_FS_HIOE_CHN_STD_INT_EN — hioe_chn_stdby_stdwn done interrupt
  [7] BIT_FS_EDCCA_ILDE_TOCNT_INT_EN — when edcca is low after tbtt, start timer,when timeout for few times(0x180~0x188),set this interrupt
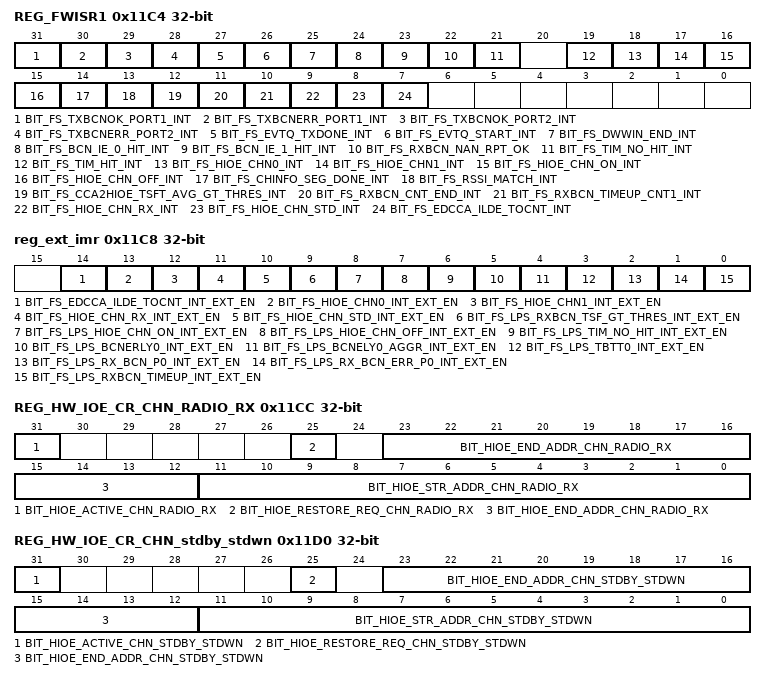
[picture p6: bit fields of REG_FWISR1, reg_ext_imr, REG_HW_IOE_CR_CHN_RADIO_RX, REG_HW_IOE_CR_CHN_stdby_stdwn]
0x11C4 REG_FWISR1 ro
  [31] BIT_FS_TXBCNOK_PORT1_INT — PORT1 TX beacon OK interrupt
  [30] BIT_FS_TXBCNERR_PORT1_INT — PORT0 TX beacon Error interrupt
  [29] BIT_FS_TXBCNOK_PORT2_INT — PORT2 TX beacon OK interrupt
  [28] BIT_FS_TXBCNERR_PORT2_INT — PORT2 TX beacon Error interrupt
  [27] BIT_FS_EVTQ_TXDONE_INT
  [26] BIT_FS_EVTQ_START_INT
  [25] BIT_FS_DWWIN_END_INT
  [24] BIT_FS_BCN_IE_0_HIT_INT — rx bcn with ie0 hit
  [23] BIT_FS_BCN_IE_1_HIT_INT — rx bcn with ie1 hit
  [22] BIT_FS_RXBCN_NAN_RPT_OK — port2 rxbcn rpt and write to txrptbuf ok
  [21] BIT_FS_TIM_NO_HIT_INT — when no my aid or aid is 0(0x16DC[8]) or my bssid is not in tim element(0x16DB[31]),generate this interrupt
  [19] BIT_FS_TIM_HIT_INT — when my aid or aid is 0 (0x16DC[8]=0) or my bssid is in tim element(0x16D8[31]=0),generate this interrupt
  [18] BIT_FS_HIOE_CHN0_INT — hioe_chn0 done interrupt
  [17] BIT_FS_HIOE_CHN1_INT — hioe_chn1 done interrupt
  [16] BIT_FS_HIOE_CHN_ON_INT — hioe_chn_on done interrupt
  [15] BIT_FS_HIOE_CHN_OFF_INT — hioe_chn_off done interrupt
  [14] BIT_FS_CHINFO_SEG_DONE_INT — indicate one channel info segment is received ok
  [13] BIT_FS_RSSI_MATCH_INT — Interrupt to inform km0 received RSSI is in supposed range
  [12] BIT_FS_CCA2HIOE_TSFT_AVG_GT_THRES_INT — If the BIT_TSFT_AVG_VALUE exceeds the BIT_TSFT_AVG_THRES several times in a row, and the number exceeds the BIT_TSFT_AVG_GT_THRES_CNT_MAX, generate an interrupt.
  [11] BIT_FS_RXBCN_CNT_END_INT — Generate the interrupt when RXBCN period cnt == 2^ BIT_RXBCN_CNT_PRD
  [10] BIT_FS_RXBCN_TIMEUP_CNT1_INT — the interrupt is issued when RX beacon frame timeout occurs specified times in port0.specified by 0x10A[22:16](only enabled when 0x17C[26]=1)
  [9] BIT_FS_HIOE_CHN_RX_INT — hioe_chn_radio_rx done interrupt
  [8] BIT_FS_HIOE_CHN_STD_INT — hioe_chn_stdby_stdwn done interrupt
  [7] BIT_FS_EDCCA_ILDE_TOCNT_INT — when edcca is low after tbtt, start timer,when timeout for few times(0x180~0x188),set this interrupt
0x11C8 reg_ext_imr — extra interrupt mask
  [14] BIT_FS_EDCCA_ILDE_TOCNT_INT_EXT_EN — when edcca is low after tbtt, start timer,when timeout for few times(0x180~0x188),set this interrupt
  [13] BIT_FS_HIOE_CHN0_INT_EXT_EN — hioe_chn0 done interrupt
  [12] BIT_FS_HIOE_CHN1_INT_EXT_EN — hioe_chn1 done interrupt
  [11] BIT_FS_HIOE_CHN_RX_INT_EXT_EN — hioe_chn_radio_rx done interrupt
  [10] BIT_FS_HIOE_CHN_STD_INT_EXT_EN — hioe_chn_stdby_stdwn done interrupt
  [9] BIT_FS_LPS_RXBCN_TSF_GT_THRES_INT_EXT_EN — The interrupt is issued when difference of tsft in beacon frame of port0 is greater than threshold
  [8] BIT_FS_LPS_HIOE_CHN_ON_INT_EXT_EN — hioe_chn_on done interrupt
  [7] BIT_FS_LPS_HIOE_CHN_OFF_INT_EXT_EN — hioe_chn_off done interrupt
  [6] BIT_FS_LPS_TIM_NO_HIT_INT_EXT_EN — when no my aid or aid is 0(0x16DC[8]) or my bssid is not in tim element(0x16DB[31]),generate this interrupt
  [5] BIT_FS_LPS_BCNERLY0_INT_EXT_EN — This interrupt is issued at the time set by DRVERLYINT register before TBTT0_MB0 time.
  [4] BIT_FS_LPS_BCNELY0_AGGR_INT_EXT_EN — port 0 Beacon early aggregation interrupt
  [3] BIT_FS_LPS_TBTT0_INT_EXT_EN — the interrupt from the exact TBTT time for P0 MBSSID0.
  [2] BIT_FS_LPS_RX_BCN_P0_INT_EXT_EN — When this bit is enable, the interrupt is issued when RX beacon frame occurs in port0.
  [1] BIT_FS_LPS_RX_BCN_ERR_P0_INT_EXT_EN — When this bit is enable, the interrupt is issued when RX beacon frame with fcs error occurs in port0.
  [0] BIT_FS_LPS_RXBCN_TIMEUP_INT_EXT_EN — When this bit is enable, the interrupt is issued when RX beacon frame timeout occurs in port0.
0x11CC REG_HW_IOE_CR_CHN_RADIO_RX access per field
  [31] BIT_HIOE_ACTIVE_CHN_RADIO_RX ro — indicate HIOE CHN_RADIO_RX is active
  [25] BIT_HIOE_RESTORE_REQ_CHN_RADIO_RX ro — RF rx mode request, clear by hw
  [23:12] BIT_HIOE_END_ADDR_CHN_RADIO_RX rw — HIOE command end address in txpktbuffer, unit:8byte
  [11:0] BIT_HIOE_STR_ADDR_CHN_RADIO_RX rw — HIOE command start address in txpktbuffer, unit:8byte
0x11D0 REG_HW_IOE_CR_CHN_stdby_stdwn access per field
  [31] BIT_HIOE_ACTIVE_CHN_STDBY_STDWN ro — indicate HIOE CHN_stdby_stdwn is active
  [25] BIT_HIOE_RESTORE_REQ_CHN_STDBY_STDWN ro — RF standby or shutdown request, clear by hw
  [23:12] BIT_HIOE_END_ADDR_CHN_STDBY_STDWN rw — HIOE command end address in txpktbuffer, unit:8byte
  [11:0] BIT_HIOE_STR_ADDR_CHN_STDBY_STDWN rw — HIOE command start address in txpktbuffer, unit:8byte
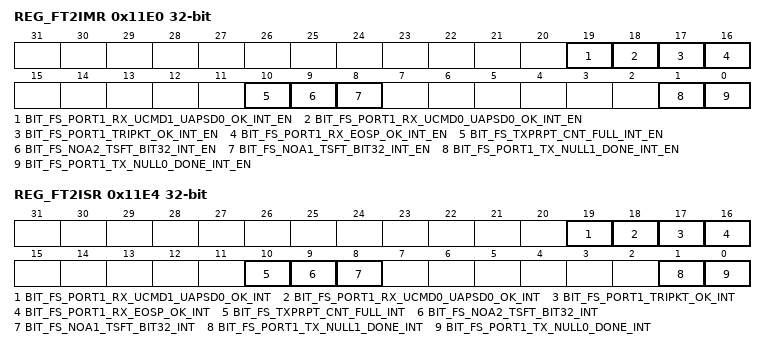
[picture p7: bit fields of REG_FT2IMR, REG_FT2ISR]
0x11E0 REG_FT2IMR access per field
  [19] BIT_FS_PORT1_RX_UCMD1_UAPSD0_OK_INT_EN rw — PORT1 rx unicast packet ok interrupt with more data =1 & UAPSD =0
  [18] BIT_FS_PORT1_RX_UCMD0_UAPSD0_OK_INT_EN rw — PORT1 rx unicast packet ok interrupt with more data =0 & UAPSD =0
  [17] BIT_FS_PORT1_TRIPKT_OK_INT_EN rw — PORT1 trigger packet assign to queue or release interrupt
  [16] BIT_FS_PORT1_RX_EOSP_OK_INT_EN rw — PORT1 RX packet with EOSP =1 ok interrupt
  [10] BIT_FS_TXPRPT_CNT_FULL_INT_EN rw — txrpt buffer full interrupt
  [9] BIT_FS_NOA2_TSFT_BIT32_INT_EN rw — NOA unit2 TSFT bit 32 toggle interrupt
  [8] BIT_FS_NOA1_TSFT_BIT32_INT_EN rw — NOA unit1 TSFT bit 32 toggle interrupt
  [1] BIT_FS_PORT1_TX_NULL1_DONE_INT_EN rw — PORT1 TX NULL1 packet ok interrupt
  [0] BIT_FS_PORT1_TX_NULL0_DONE_INT_EN rw — PORT1 TX NULL0 packet ok interrupt
0x11E4 REG_FT2ISR ro
  [19] BIT_FS_PORT1_RX_UCMD1_UAPSD0_OK_INT — PORT1 rx unicast packet ok interrupt with more data =1 & UAPSD =0
  [18] BIT_FS_PORT1_RX_UCMD0_UAPSD0_OK_INT — PORT1 rx unicast packet ok interrupt with more data =0 & UAPSD =0
  [17] BIT_FS_PORT1_TRIPKT_OK_INT — PORT1 trigger packet assign to queue or release interrupt
  [16] BIT_FS_PORT1_RX_EOSP_OK_INT — PORT1 RX packet with EOSP =1 ok interrupt
  [10] BIT_FS_TXPRPT_CNT_FULL_INT — txrpt buffer full interrupt
  [9] BIT_FS_NOA2_TSFT_BIT32_INT — NOA unit2 TSFT bit 32 toggle interrupt
  [8] BIT_FS_NOA1_TSFT_BIT32_INT — NOA unit1 TSFT bit 32 toggle interrupt
  [1] BIT_FS_PORT1_TX_NULL1_DONE_INT — PORT1 TX NULL1 packet ok interrupt
  [0] BIT_FS_PORT1_TX_NULL0_DONE_INT — PORT1 TX NULL0 packet ok interrupt
{0x11E8+4i} REG_MSG{i} (i=2..5)
  [31:0] BIT_FW_MSG{i} — fw message {i}
